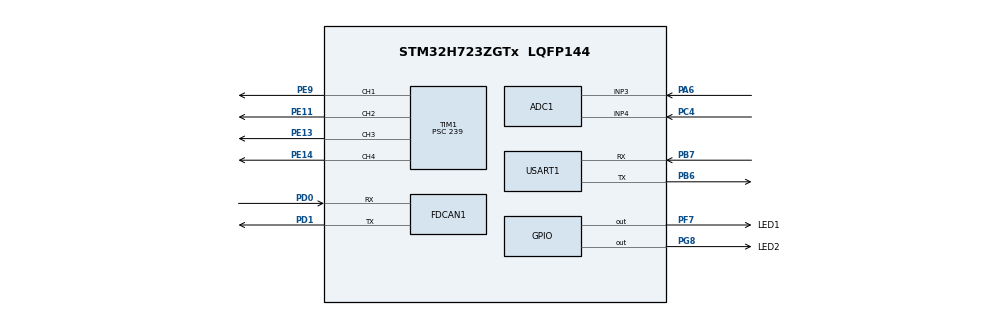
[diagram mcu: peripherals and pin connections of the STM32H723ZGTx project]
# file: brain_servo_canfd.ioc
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ADC1.Channel-0\#ChannelRegularConversion=ADC_CHANNEL_3
ADC1.Channel-1\#ChannelRegularConversion=ADC_CHANNEL_3
ADC1.ClockPrescaler=ADC_CLOCK_SYNC_PCLK_DIV4
ADC1.ContinuousConvMode=ENABLE
ADC1.ConversionDataManagement=ADC_CONVERSIONDATA_DMA_CIRCULAR
ADC1.NbrOfConversion=2
ADC1.NbrOfConversionFlag=1
ADC1.OffsetNumber-0\#ChannelRegularConversion=ADC_OFFSET_NONE
ADC1.OffsetNumber-1\#ChannelRegularConversion=ADC_OFFSET_NONE
ADC1.OffsetSignedSaturation-0\#ChannelRegularConversion=DISABLE
ADC1.OffsetSignedSaturation-1\#ChannelRegularConversion=DISABLE
ADC1.Rank-0\#ChannelRegularConversion=1
ADC1.Rank-1\#ChannelRegularConversion=2
ADC1.SamplingTime-0\#ChannelRegularConversion=ADC_SAMPLETIME_1CYCLE_5
ADC1.SamplingTime-1\#ChannelRegularConversion=ADC_SAMPLETIME_1CYCLE_5
ADC1.master=1
CORTEX_M7.default_mode_Activation=1
Dma.ADC1.2.Direction=DMA_PERIPH_TO_MEMORY
Dma.ADC1.2.EventEnable=DISABLE
Dma.ADC1.2.FIFOMode=DMA_FIFOMODE_DISABLE
Dma.ADC1.2.Instance=DMA1_Stream2
Dma.ADC1.2.MemDataAlignment=DMA_MDATAALIGN_HALFWORD
Dma.ADC1.2.MemInc=DMA_MINC_ENABLE
Dma.ADC1.2.Mode=DMA_NORMAL
Dma.ADC1.2.PeriphDataAlignment=DMA_PDATAALIGN_HALFWORD
Dma.ADC1.2.PeriphInc=DMA_PINC_DISABLE
Dma.ADC1.2.Polarity=HAL_DMAMUX_REQ_GEN_RISING
Dma.ADC1.2.Priority=DMA_PRIORITY_LOW
Dma.ADC1.2.RequestNumber=1
Dma.ADC1.2.SignalID=NONE
Dma.ADC1.2.SyncEnable=DISABLE
Dma.ADC1.2.SyncPolarity=HAL_DMAMUX_SYNC_NO_EVENT
Dma.ADC1.2.SyncRequestNumber=1
Dma.ADC1.2.SyncSignalID=NONE
Dma.Request0=USART1_RX
Dma.Request1=USART1_TX
Dma.Request2=ADC1
Dma.USART1_RX.0.Direction=DMA_PERIPH_TO_MEMORY
Dma.USART1_RX.0.EventEnable=DISABLE
Dma.USART1_RX.0.FIFOMode=DMA_FIFOMODE_DISABLE
Dma.USART1_RX.0.Instance=DMA1_Stream0
Dma.USART1_RX.0.MemDataAlignment=DMA_MDATAALIGN_BYTE
Dma.USART1_RX.0.MemInc=DMA_MINC_ENABLE
Dma.USART1_RX.0.Mode=DMA_NORMAL
Dma.USART1_RX.0.PeriphDataAlignment=DMA_PDATAALIGN_BYTE
Dma.USART1_RX.0.PeriphInc=DMA_PINC_DISABLE
Dma.USART1_RX.0.Polarity=HAL_DMAMUX_REQ_GEN_RISING
Dma.USART1_RX.0.Priority=DMA_PRIORITY_MEDIUM
Dma.USART1_RX.0.RequestNumber=1
Dma.USART1_RX.0.SignalID=NONE
Dma.USART1_RX.0.SyncEnable=DISABLE
Dma.USART1_RX.0.SyncPolarity=HAL_DMAMUX_SYNC_NO_EVENT
Dma.USART1_RX.0.SyncRequestNumber=1
Dma.USART1_RX.0.SyncSignalID=NONE
Dma.USART1_TX.1.Direction=DMA_MEMORY_TO_PERIPH
Dma.USART1_TX.1.EventEnable=DISABLE
Dma.USART1_TX.1.FIFOMode=DMA_FIFOMODE_DISABLE
Dma.USART1_TX.1.Instance=DMA1_Stream1
Dma.USART1_TX.1.MemDataAlignment=DMA_MDATAALIGN_BYTE
Dma.USART1_TX.1.MemInc=DMA_MINC_ENABLE
Dma.USART1_TX.1.Mode=DMA_NORMAL
Dma.USART1_TX.1.PeriphDataAlignment=DMA_PDATAALIGN_BYTE
Dma.USART1_TX.1.PeriphInc=DMA_PINC_DISABLE
Dma.USART1_TX.1.Polarity=HAL_DMAMUX_REQ_GEN_RISING
Dma.USART1_TX.1.Priority=DMA_PRIORITY_LOW
Dma.USART1_TX.1.RequestNumber=1
Dma.USART1_TX.1.SignalID=NONE
Dma.USART1_TX.1.SyncEnable=DISABLE
Dma.USART1_TX.1.SyncPolarity=HAL_DMAMUX_SYNC_NO_EVENT
Dma.USART1_TX.1.SyncRequestNumber=1
Dma.USART1_TX.1.SyncSignalID=NONE
FDCAN1.CalculateBaudRateNominal=333333
FDCAN1.CalculateTimeBitNominal=3000
FDCAN1.CalculateTimeQuantumNominal=1000.0
FREERTOS.Tasks01=defaultTask,24,128,StartDefaultTask,Default,NULL,Dynamic,NULL,NULL
FREERTOS.configTOTAL_HEAP_SIZE=65536
FREERTOS.configUSE_TICK_HOOK=1
IWDG1.Prescaler=IWDG_PRESCALER_32
Mcu.Family=STM32H7
Mcu.Name=STM32H723ZGTx
Mcu.Package=LQFP144
NVIC.DMA1_Stream0_IRQn=true\:5\:0\:false\:false\:true\:true\:false\:true\:true
NVIC.DMA1_Stream1_IRQn=true\:5\:0\:false\:false\:true\:true\:false\:true\:true
NVIC.DMA1_Stream2_IRQn=true\:5\:0\:false\:false\:true\:true\:false\:true\:true
NVIC.PriorityGroup=NVIC_PRIORITYGROUP_4
NVIC.USART1_IRQn=true\:5\:0\:false\:false\:true\:true\:true\:true\:true
PA13(JTMS/SWDIO).Mode=Serial_Wire
PA13(JTMS/SWDIO).Signal=DEBUG_JTMS-SWDIO
PA14(JTCK/SWCLK).Mode=Serial_Wire
PA14(JTCK/SWCLK).Signal=DEBUG_JTCK-SWCLK
PA6.Signal=ADCx_INP3
PB6.Mode=Asynchronous
PB6.Signal=USART1_TX
PB7.GPIO_PuPd=GPIO_PULLUP
PB7.Mode=Asynchronous
PB7.Signal=USART1_RX
PC4.Signal=ADCx_INP4
PD0.Mode=FDCAN_Activate
PD0.Signal=FDCAN1_RX
PD1.Mode=FDCAN_Activate
PD1.Signal=FDCAN1_TX
PE11.Signal=S_TIM1_CH2
PE13.Signal=S_TIM1_CH3
PE14.Signal=S_TIM1_CH4
PE9.Signal=S_TIM1_CH1
PF7.GPIO_Label=LED1
PF7.Signal=GPIO_Output
PG8.GPIO_Label=LED2
PG8.Signal=GPIO_Output
PH0-OSC_IN.Mode=HSE-External-Oscillator
PH0-OSC_IN.Signal=RCC_OSC_IN
PH1-OSC_OUT.Mode=HSE-External-Oscillator
PH1-OSC_OUT.Signal=RCC_OSC_OUT
ProjectManager.HeapSize=0x1000
ProjectManager.StackSize=0x400
ProjectManager.TargetToolchain=STM32CubeIDE
RCC.ADCFreq_Value=96000000
RCC.APB1Freq_Value=120000000
RCC.APB2Freq_Value=120000000
RCC.APB3Freq_Value=120000000
RCC.APB4Freq_Value=120000000
RCC.CortexFreq_Value=240000000
RCC.D1PPRE=RCC_APB3_DIV2
RCC.D2PPRE1=RCC_APB1_DIV2
RCC.D2PPRE2=RCC_APB2_DIV2
RCC.D3PPRE=RCC_APB4_DIV2
RCC.DIVM1=1
RCC.DIVM2=1
RCC.DIVM3=1
RCC.DIVN1=15
RCC.DIVN2=12
RCC.DIVN3=12
RCC.DIVP1=1
RCC.FDCANCLockSelection=RCC_FDCANCLKSOURCE_HSE
RCC.HCLKFreq_Value=240000000
RCC.HSE_VALUE=16000000
RCC.PLLSourceVirtual=RCC_PLLSOURCE_HSE
RCC.PWR_Regulator_Voltage_Scale=PWR_REGULATOR_VOLTAGE_SCALE0
RCC.SYSCLKFreq_VALUE=240000000
RCC.SYSCLKSource=RCC_SYSCLKSOURCE_PLLCLK
RCC.USBFreq_Value=120000000
SH.ADCx_INP3.0=ADC1_INP3,IN3-Single-Ended
SH.ADCx_INP4.0=ADC1_INP4,IN4-Single-Ended
SH.S_TIM1_CH1.0=TIM1_CH1,PWM Generation1 CH1
SH.S_TIM1_CH2.0=TIM1_CH2,PWM Generation2 CH2
SH.S_TIM1_CH3.0=TIM1_CH3,PWM Generation3 CH3
SH.S_TIM1_CH4.0=TIM1_CH4,PWM Generation4 CH4
TIM1.AutoReloadPreload=TIM_AUTORELOAD_PRELOAD_ENABLE
TIM1.Channel-PWM\ Generation1\ CH1=TIM_CHANNEL_1
TIM1.Channel-PWM\ Generation2\ CH2=TIM_CHANNEL_2
TIM1.Channel-PWM\ Generation3\ CH3=TIM_CHANNEL_3
TIM1.Channel-PWM\ Generation4\ CH4=TIM_CHANNEL_4
TIM1.Prescaler=239
TIM1.Pulse-PWM\ Generation1\ CH1=1500
TIM1.Pulse-PWM\ Generation2\ CH2=1500
TIM1.Pulse-PWM\ Generation3\ CH3=1500
TIM1.Pulse-PWM\ Generation4\ CH4=1500
USART1.VirtualMode-Asynchronous=VM_ASYNC
VP_FREERTOS_VS_CMSIS_V2.Mode=CMSIS_V2
VP_IWDG1_VS_IWDG.Mode=IWDG_Activate
VP_MEMORYMAP_VS_MEMORYMAP.Mode=CurAppReg
VP_RTC_VS_RTC_Activate.Mode=RTC_Enabled
VP_TIM1_VS_ClockSourceINT.Mode=Internal
board=custom

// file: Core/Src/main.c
/* USER CODE BEGIN Header */
/**
  ******************************************************************************
  * @file           : main.c
  * @brief          : Main program body
  ******************************************************************************
  * @attention
  *
  * Copyright (c) 2026 STMicroelectronics.
  * All rights reserved.
  *
  * This software is licensed under terms that can be found in the LICENSE file
  * in the root directory of this software component.
  * If no LICENSE file comes with this software, it is provided AS-IS.
  *
  ******************************************************************************
  */
/* USER CODE END Header */
#include "main.h"
#include "FreeRTOS.h"
#include "cmsis_os2.h"
#include "adc.h"
#include "dma.h"
#include "fdcan.h"
#include "iwdg.h"
#include "rtc.h"
#include "tim.h"
#include "usart.h"
#include "gpio.h"

/* USER CODE BEGIN Includes */
#include <string.h>
#include <stdio.h>
/* USER CODE END Includes */

/* USER CODE BEGIN PD */
#define VECT_TAB_OFFSET  0x00020200UL // 必须与 flash_if.h 中的起始地址对应
/* USER CODE END PD */

void SystemClock_Config(void);
static void MPU_Config(void);
void MX_FREERTOS_Init(void);

int main(void)
{

  /* USER CODE BEGIN 1 */
  SCB->VTOR = FLASH_BANK1_BASE | VECT_TAB_OFFSET;
  __enable_irq(); // 因为bootloader里面跳转之前关闭了中断，所以这里要开启
  /* USER CODE END 1 */

  /* MPU Configuration--------------------------------------------------------*/
  MPU_Config();

  /* MCU Configuration--------------------------------------------------------*/

  /* Reset of all peripherals, Initializes the Flash interface and the Systick. */
  HAL_Init();

  /* Configure the system clock */
  SystemClock_Config();

  /* Initialize all configured peripherals */
  MX_GPIO_Init();
  MX_DMA_Init();
  MX_FDCAN1_Init();
  MX_IWDG1_Init();
  MX_TIM1_Init();
  MX_USART1_UART_Init();
  MX_ADC1_Init();
  MX_RTC_Init();
  /* USER CODE BEGIN 2 */

  __HAL_DBGMCU_FREEZE_IWDG1(); // 调试时冻结看门狗

  /* USER CODE END 2 */

  /* Init scheduler */
  osKernelInitialize();  /* Call init function for freertos objects (in cmsis_os2.c) */
  MX_FREERTOS_Init();

  /* Start scheduler */
  osKernelStart();

  /* We should never get here as control is now taken by the scheduler */

  /* Infinite loop */
  while (1)
  {

  }
}

void SystemClock_Config(void)
{
  RCC_OscInitTypeDef RCC_OscInitStruct = {0};
  RCC_ClkInitTypeDef RCC_ClkInitStruct = {0};

  /** Supply configuration update enable
  */
  HAL_PWREx_ConfigSupply(PWR_LDO_SUPPLY);

  /** Configure the main internal regulator output voltage
  */
  __HAL_PWR_VOLTAGESCALING_CONFIG(PWR_REGULATOR_VOLTAGE_SCALE0);

  while(!__HAL_PWR_GET_FLAG(PWR_FLAG_VOSRDY)) {}

  /** Initializes the RCC Oscillators according to the specified parameters
  * in the RCC_OscInitTypeDef structure.
  */
  RCC_OscInitStruct.OscillatorType = RCC_OSCILLATORTYPE_LSI|RCC_OSCILLATORTYPE_HSE;
  RCC_OscInitStruct.HSEState = RCC_HSE_ON;
  RCC_OscInitStruct.LSIState = RCC_LSI_ON;
  RCC_OscInitStruct.PLL.PLLState = RCC_PLL_ON;
  RCC_OscInitStruct.PLL.PLLSource = RCC_PLLSOURCE_HSE;
  RCC_OscInitStruct.PLL.PLLM = 1;
  RCC_OscInitStruct.PLL.PLLN = 15;
  RCC_OscInitStruct.PLL.PLLP = 1;
  RCC_OscInitStruct.PLL.PLLQ = 2;
  RCC_OscInitStruct.PLL.PLLR = 2;
  RCC_OscInitStruct.PLL.PLLRGE = RCC_PLL1VCIRANGE_3;
  RCC_OscInitStruct.PLL.PLLVCOSEL = RCC_PLL1VCOWIDE;
  RCC_OscInitStruct.PLL.PLLFRACN = 0;
  if (HAL_RCC_OscConfig(&RCC_OscInitStruct) != HAL_OK)
  {
    Error_Handler();
  }

  /** Initializes the CPU, AHB and APB buses clocks
  */
  RCC_ClkInitStruct.ClockType = RCC_CLOCKTYPE_HCLK|RCC_CLOCKTYPE_SYSCLK
                              |RCC_CLOCKTYPE_PCLK1|RCC_CLOCKTYPE_PCLK2
                              |RCC_CLOCKTYPE_D3PCLK1|RCC_CLOCKTYPE_D1PCLK1;
  RCC_ClkInitStruct.SYSCLKSource = RCC_SYSCLKSOURCE_PLLCLK;
  RCC_ClkInitStruct.SYSCLKDivider = RCC_SYSCLK_DIV1;
  RCC_ClkInitStruct.AHBCLKDivider = RCC_HCLK_DIV1;
  RCC_ClkInitStruct.APB3CLKDivider = RCC_APB3_DIV2;
  RCC_ClkInitStruct.APB1CLKDivider = RCC_APB1_DIV2;
  RCC_ClkInitStruct.APB2CLKDivider = RCC_APB2_DIV2;
  RCC_ClkInitStruct.APB4CLKDivider = RCC_APB4_DIV2;

  if (HAL_RCC_ClockConfig(&RCC_ClkInitStruct, FLASH_LATENCY_3) != HAL_OK)
  {
    Error_Handler();
  }
}

 /* MPU Configuration */

void MPU_Config(void)
{
  MPU_Region_InitTypeDef MPU_InitStruct = {0};

  /* Disables the MPU */
  HAL_MPU_Disable();

  /** Initializes and configures the Region and the memory to be protected
  */
  MPU_InitStruct.Enable = MPU_REGION_ENABLE;
  MPU_InitStruct.Number = MPU_REGION_NUMBER0;
  MPU_InitStruct.BaseAddress = 0x0;
  MPU_InitStruct.Size = MPU_REGION_SIZE_4GB;
  MPU_InitStruct.SubRegionDisable = 0x87;
  MPU_InitStruct.TypeExtField = MPU_TEX_LEVEL0;
  MPU_InitStruct.AccessPermission = MPU_REGION_NO_ACCESS;
  MPU_InitStruct.DisableExec = MPU_INSTRUCTION_ACCESS_DISABLE;
  MPU_InitStruct.IsShareable = MPU_ACCESS_SHAREABLE;
  MPU_InitStruct.IsCacheable = MPU_ACCESS_NOT_CACHEABLE;
  MPU_InitStruct.IsBufferable = MPU_ACCESS_NOT_BUFFERABLE;

  HAL_MPU_ConfigRegion(&MPU_InitStruct);
  /* Enables the MPU */
  HAL_MPU_Enable(MPU_PRIVILEGED_DEFAULT);

}

void Error_Handler(void)
{
  /* USER CODE BEGIN Error_Handler_Debug */
	printf("\r\n[APP] Crashed in Error_Handler!\r\n");

  /* User can add his own implementation to report the HAL error return state */
  __disable_irq();
  while (1)
  {
  }
  /* USER CODE END Error_Handler_Debug */
}

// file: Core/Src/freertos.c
/* USER CODE BEGIN Header */
/**
  ******************************************************************************
  * File Name          : freertos.c
  * Description        : Code for freertos applications
  ******************************************************************************
  * @attention
  *
  * Copyright (c) 2026 STMicroelectronics.
  * All rights reserved.
  *
  * This software is licensed under terms that can be found in the LICENSE file
  * in the root directory of this software component.
  * If no LICENSE file comes with this software, it is provided AS-IS.
  *
  ******************************************************************************
  */
/* USER CODE END Header */

#include "FreeRTOS.h"
#include "task.h"
#include "main.h"
#include "FreeRTOS.h"
#include "cmsis_os2.h"

/* USER CODE BEGIN Includes */
#include "user_TasksInit.h"

/* USER CODE END Includes */

/* Definitions for defaultTask */
osThreadId_t defaultTaskHandle;
const osThreadAttr_t defaultTask_attributes = {
  .name = "defaultTask",
  .stack_size = 128 * 4,
  .priority = (osPriority_t) osPriorityNormal,
};

void StartDefaultTask(void *argument);

void MX_FREERTOS_Init(void); /* (MISRA C 2004 rule 8.1) */

/* Hook prototypes */
void vApplicationTickHook(void);

/* USER CODE BEGIN 3 */
void vApplicationTickHook( void )
{
   /* This function will be called by each tick interrupt if
   configUSE_TICK_HOOK is set to 1 in FreeRTOSConfig.h. User code can be
   added here, but the tick hook is called from an interrupt context, so
   code must not attempt to block, and only the interrupt safe FreeRTOS API
   functions can be used (those that end in FromISR()). */
	TaskTickHook();
}
/* USER CODE END 3 */

void MX_FREERTOS_Init(void) {
  /* USER CODE BEGIN Init */
  User_Tasks_Init();
  /* USER CODE END Init */

  /* Create the thread(s) */
  /* creation of defaultTask */
  defaultTaskHandle = osThreadNew(StartDefaultTask, NULL, &defaultTask_attributes);

}

void StartDefaultTask(void *argument)
{
  /* USER CODE BEGIN StartDefaultTask */
  /* Infinite loop */
  for(;;)
  {
    osDelay(2);
  }
  /* USER CODE END StartDefaultTask */
}
